# SF32LB57x register map
File version: 1.0
CPU: CM33 r0p1, little endian, MPU, FPU, 3 interrupt priority bits
Registers are 32-bit, read-write, reset 0x0 unless marked. A register's access mark holds for its fields unless they carry their own. Offsets are from the block's base; [hi:lo] are bit positions.

## BTIM1
Base 0x50092000
Same registers: BTIM3 0x40009000, BTIM4 0x4000A000, BTIM2 0x500B1000
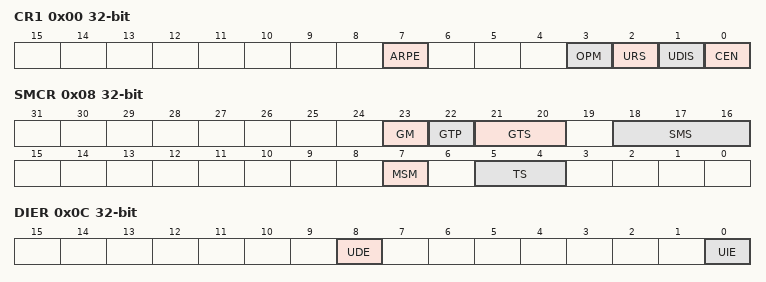
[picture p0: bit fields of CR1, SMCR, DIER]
0x00 CR1 — TIM control register 1
  [7] ARPE — Auto-reload preload enable 0: TIMx_ARR register is not buffered 1: TIMx_ARR register is buffered
  [3] OPM — One-pulse mode 0: Counter is not stopped at update event 1: Counter stops counting at the next update event (clearing the bit CEN)
  [2] URS — Update request source This bit is set and cleared by software to select the UEV event sources. 0: Any of the following events generate an update interrupt or DMA request if enabled. These events can be: – Counter overflow – Setting the UG bit – Update generation through the slave mode controller 1: Only counter overflow generates an update interrupt or DMA request if enabled.
  [1] UDIS — Update disable This bit is set and cleared by software to enable/disable UEV event generation. 0: UEV enabled. The Update (UEV) event is generated by one of the following events: – Counter overflow – Setting the UG bit – Update generation through the slave mode controller Buffered registers are then loaded with their preload values. 1: UEV disabled. The Update event is not generated, shadow registers keep their value (ARR, PSC). However the counter and the prescaler are reinitialized if the UG bit is set or if a hardware reset is received from the slave mode controller.
  [0] CEN — Counter enable 0: Counter disabled 1: Counter enabled Note: Gated mode can work only if the CEN bit has been previously set by software. However trigger mode can set the CEN bit automatically by hardware. CEN is cleared automatically in one-pulse mode, when an update event occurs.
0x04 CR2 — TIM control register 2
  [5:4] MMS — Master mode selection These bits allow to select the information to be sent in master mode to slave timers for synchronization (TRGO). The combination is as follows: 00: Reset - the UG bit from the TIMx_EGR register is used as trigger output (TRGO). If the reset is generated by the trigger input (slave mode controller configured in reset mode) then the signal on TRGO is delayed compared to the actual reset. 01: Enable - the Counter enable signal, CNT_EN, is used as trigger output (TRGO). It is useful to start several timers at the same time or to control a window in which a slave timer is enabled. The Counter Enable signal is generated by a logic OR between CEN control bit and the trigger input when configured in gated mode. When the Counter Enable signal is controlled by the trigger input, there is a delay on TRGO, except if the master/slave mode is selected (see the MSM bit description in TIMx_SMCR register). 10: Update - The update event is selected as trigger output (TRGO). For instance a master timer can then be used as a prescaler for a slave timer. 11: Gating - The delayed gating trigger is selected as trigger output (TRGO). Note: The clock of the slave timer must be enabled prior to receive events from the master timer, and must not be changed on-the-fly while triggers are received from the master timer
0x08 SMCR — TIM slave mode control register
  [23] GM — Gated Mode. The counter clock is enabled when the selected trigger input (TRGI) is active (according to gating trigger polarity). The counter stops (but is not reset) as soon as the trigger becomes inactive. Both start and stop of the counter are controlled. Gated mode and slave mode can be enabled simutanuously with different trigger selection.
  [22] GTP — Gating trigger polarity invert 0: active at high level 1: active at low level
  [21:20] GTS — Gating trigger selection in gated mode This bit-field selects the trigger input to be used to enable the counter gating. 00: Internal Trigger 0 (ITR0) 01: Internal Trigger 1 (ITR1) 10: Internal Trigger 2 (ITR2) 11: Internal Trigger 3 (ITR3)
  [18:16] SMS — Slave mode selection When external signals are selected the active edge of the trigger signal (TRGI) is linked to the polarity selected on the external input (see Input Control register and Control Register description. 000: Slave mode disabled - if CEN = ‘1 then the prescaler is clocked directly by the internal clock. 001: Reset Mode - Rising edge of the selected trigger input (TRGI) reinitializes the counter and generates an update of the registers. 010: Trigger Mode - The counter starts at a rising edge of the trigger TRGI (but it is not reset). Only the start of the counter is controlled. 011: Combined reset + trigger mode - Rising edge of the selected trigger input (TRGI) reinitializes the counter, generates an update of the registers and starts the counter. 100: External Clock Mode - Rising edges of the selected trigger (TRGI) clock the counter.
  [7] MSM — Master/Slave mode. This bit should be asserted on master timer if synchronization if needed. 0: No action 1: The effect of an event on the trigger input (TRGI) is delayed to allow a perfect synchronization between the current timer and its slaves (through TRGO). It is useful if we want to synchronize several timers on a single external event.
  [5:4] TS — Trigger selection This bit-field selects the trigger input to be used to synchronize the counter. 00: Internal Trigger 0 (ITR0) 01: Internal Trigger 1 (ITR1) 10: Internal Trigger 2 (ITR2) 11: Internal Trigger 3 (ITR3) Note: These bits must be changed only when they are not used (e.g. when SMS=000) to avoid wrong edge detections at the transition.
0x0C DIER — TIM DMA/Interrupt enable register
  [8] UDE — Update DMA request enable 0: Update DMA request disabled. 1: Update DMA request enabled
  [0] UIE — Update interrupt enable 0: Update interrupt disabled. 1: Update interrupt enabled
0x10 SR — TIM status register
  [0] UIF — Update interrupt flag This bit is set by hardware on an update event. It is cleared by software. 0: No update occurred 1: Update interrupt pending. This bit is set by hardware when the registers are updated: At overflow and if UDIS=0 in the TIMx_CR1 register. When CNT is reinitialized by software using the UG bit in TIMx_EGR register, if URS=0 and UDIS=0 in the TIMx_CR1 register. When CNT is reinitialized by a trigger event (refer to the synchro control register description), if URS=0 and UDIS=0 in the TIMx_CR1 register.
0x14 EGR — Event generation register
  [0] UG — Update generation This bit can be set by software, it is automatically cleared by hardware. 0: No action 1: Re-initialize the counter and generates an update of the registers. Note that the prescaler counter is cleared too (anyway the prescaler ratio is not affected). The counter is cleared if the center-aligned mode is selected or if DIR=0 (upcounting), else it takes the auto-reload value (TIMx_ARR) if DIR=1 (downcounting).
0x24 CNT — Counter
  [31:0] CNT — counter value
0x28 PSC — Prescaler
  [15:0] PSC — Prescaler value The counter clock frequency CK_CNT is equal to fCK_PSC / (PSC[15:0] + 1). PSC contains the value to be loaded in the active prescaler register at each update event (including when the counter is cleared through UG bit of TIMx_EGR register or through trigger controller when configured in “reset mode”).
0x2C ARR — Auto-reload register
  [31:0] ARR — Auto-reload value ARR is the value to be loaded in the actual auto-reload register. The counter is blocked while the auto-reload value is null.
